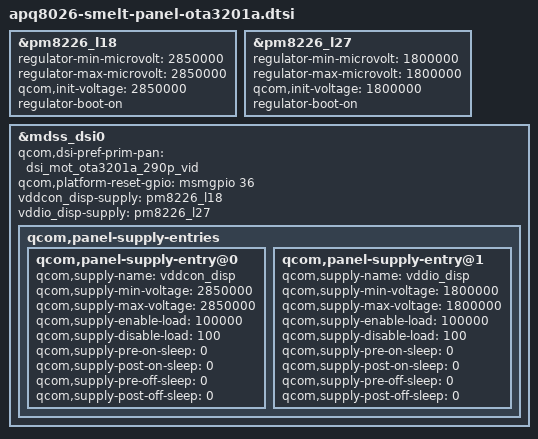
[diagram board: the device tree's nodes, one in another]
/* Copyright (c) 2014, The Linux Foundation. All rights reserved.
 *
 * This program is free software; you can redistribute it and/or modify
 * it under the terms of the GNU General Public License version 2 and
 * only version 2 as published by the Free Software Foundation.
 *
 * This program is distributed in the hope that it will be useful,
 * but WITHOUT ANY WARRANTY; without even the implied warranty of
 * MERCHANTABILITY or FITNESS FOR A PARTICULAR PURPOSE.  See the
 * GNU General Public License for more details.
 */

#include "qcom/dsi-panel-mot-ota3201a-290p-vid.dtsi"

&pm8226_l18 {
	regulator-min-microvolt = <2850000>;
	regulator-max-microvolt = <2850000>;
	qcom,init-voltage = <2850000>;
	regulator-boot-on;
};

&pm8226_l27 {
	regulator-min-microvolt = <1800000>;
	regulator-max-microvolt = <1800000>;
	qcom,init-voltage = <1800000>;
	regulator-boot-on;
};


&mdss_dsi0 {
	qcom,dsi-pref-prim-pan = <&dsi_mot_ota3201a_290p_vid>;
	qcom,platform-reset-gpio = <&msmgpio 36 0>;
	vddcon_disp-supply = <&pm8226_l18>;
	vddio_disp-supply = <&pm8226_l27>;
	qcom,panel-supply-entries {
		qcom,panel-supply-entry@0 {
			qcom,supply-name = "vddcon_disp";
			qcom,supply-min-voltage = <2850000>;
			qcom,supply-max-voltage = <2850000>;
			qcom,supply-enable-load = <100000>;
			qcom,supply-disable-load = <100>;
			qcom,supply-pre-on-sleep = <0>;
			qcom,supply-post-on-sleep = <0>;
			qcom,supply-pre-off-sleep = <0>;
			qcom,supply-post-off-sleep = <0>;
		};
		qcom,panel-supply-entry@1 {
			qcom,supply-name = "vddio_disp";
			qcom,supply-min-voltage = <1800000>;
			qcom,supply-max-voltage = <1800000>;
			qcom,supply-enable-load = <100000>;
			qcom,supply-disable-load = <100>;
			qcom,supply-pre-on-sleep = <0>;
			qcom,supply-post-on-sleep = <0>;
			qcom,supply-pre-off-sleep = <0>;
			qcom,supply-post-off-sleep = <0>;
		};
	};
};
